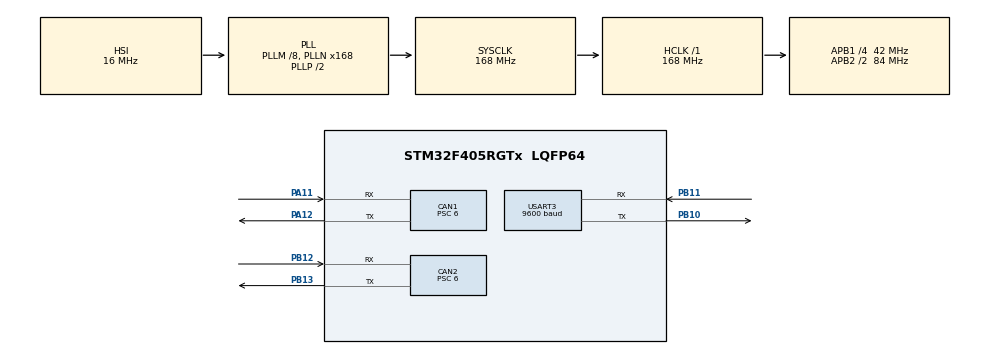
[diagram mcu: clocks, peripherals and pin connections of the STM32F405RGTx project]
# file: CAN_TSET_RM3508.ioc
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CAN1.BS1=CAN_BS1_4TQ
CAN1.BS2=CAN_BS2_2TQ
CAN1.CalculateBaudRate=1000000
CAN1.CalculateTimeBit=1000
CAN1.CalculateTimeQuantum=142.85714285714286
CAN1.Prescaler=6
CAN2.BS1=CAN_BS1_4TQ
CAN2.BS2=CAN_BS2_2TQ
CAN2.CalculateBaudRate=1000000
CAN2.CalculateTimeBit=1000
CAN2.CalculateTimeQuantum=142.85714285714286
CAN2.Prescaler=6
Mcu.Family=STM32F4
Mcu.Name=STM32F405RGTx
Mcu.Package=LQFP64
NVIC.CAN1_RX0_IRQn=true\:0\:0\:false\:false\:true\:true\:true\:true
NVIC.CAN1_SCE_IRQn=true\:0\:0\:false\:false\:true\:true\:true\:true
NVIC.CAN2_RX1_IRQn=true\:0\:0\:false\:false\:true\:true\:true\:true
NVIC.CAN2_SCE_IRQn=true\:0\:0\:false\:false\:true\:true\:true\:true
NVIC.PriorityGroup=NVIC_PRIORITYGROUP_4
NVIC.USART3_IRQn=true\:0\:0\:false\:false\:true\:true\:true\:true
PA11.Mode=CAN_Activate
PA11.Signal=CAN1_RX
PA12.Mode=CAN_Activate
PA12.Signal=CAN1_TX
PA13.Mode=Serial_Wire
PA13.Signal=SYS_JTMS-SWDIO
PA14.Mode=Serial_Wire
PA14.Signal=SYS_JTCK-SWCLK
PB10.Mode=Asynchronous
PB10.Signal=USART3_TX
PB11.Mode=Asynchronous
PB11.Signal=USART3_RX
PB12.Mode=CAN_Activate
PB12.Signal=CAN2_RX
PB13.Mode=CAN_Activate
PB13.Signal=CAN2_TX
PC14-OSC32_IN.Mode=LSE-External-Oscillator
PC14-OSC32_IN.Signal=RCC_OSC32_IN
PC15-OSC32_OUT.Mode=LSE-External-Oscillator
PC15-OSC32_OUT.Signal=RCC_OSC32_OUT
PH0-OSC_IN.Mode=HSE-External-Oscillator
PH0-OSC_IN.Signal=RCC_OSC_IN
PH1-OSC_OUT.Mode=HSE-External-Oscillator
PH1-OSC_OUT.Signal=RCC_OSC_OUT
ProjectManager.HeapSize=0x200
ProjectManager.StackSize=0x400
ProjectManager.TargetToolchain=MDK-ARM V5
RCC.48MHZClocksFreq_Value=84000000
RCC.AHBFreq_Value=168000000
RCC.APB1CLKDivider=RCC_HCLK_DIV4
RCC.APB1Freq_Value=42000000
RCC.APB1TimFreq_Value=84000000
RCC.APB2CLKDivider=RCC_HCLK_DIV2
RCC.APB2Freq_Value=84000000
RCC.APB2TimFreq_Value=168000000
RCC.CortexFreq_Value=168000000
RCC.HCLKFreq_Value=168000000
RCC.HSE_VALUE=25000000
RCC.HSI_VALUE=16000000
RCC.PLLM=8
RCC.PLLN=168
RCC.SYSCLKFreq_VALUE=168000000
RCC.SYSCLKSource=RCC_SYSCLKSOURCE_PLLCLK
RCC.VCOOutputFreq_Value=336000000
USART3.BaudRate=9600
USART3.VirtualMode=VM_ASYNC
board=custom

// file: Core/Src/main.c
/* USER CODE BEGIN Header */
/**
  ******************************************************************************
  * @file           : main.c
  * @brief          : Main program body
  ******************************************************************************
  * @attention
  *
  * Copyright (c) 2023 STMicroelectronics.
  * All rights reserved.
  *
  * This software is licensed under terms that can be found in the LICENSE file
  * in the root directory of this software component.
  * If no LICENSE file comes with this software, it is provided AS-IS.
  *
  ******************************************************************************
  */
/* USER CODE END Header */
#include "main.h"
#include "can.h"
#include "usart.h"
#include "gpio.h"

/* USER CODE BEGIN Includes */
#include "can_bsp.h"
#include "RM3508.h"

/* USER CODE END Includes */

void SystemClock_Config(void);

int main(void)
{

  /* MCU Configuration--------------------------------------------------------*/

  /* Reset of all peripherals, Initializes the Flash interface and the Systick. */
  HAL_Init();

  /* Configure the system clock */
  SystemClock_Config();

  /* Initialize all configured peripherals */
  MX_GPIO_Init();
  MX_CAN1_Init();
  MX_CAN2_Init();
  MX_USART3_UART_Init();
  /* USER CODE BEGIN 2 */
	CAN_Init(&hcan1);
	CAN_Init(&hcan2);

  /* USER CODE END 2 */

  /* Infinite loop */
  while (1)
  {

    /* USER CODE BEGIN 3 */

		RM3508_Set_Speed(1000,0x03);

		HAL_Delay(1);

//		sprintf(txdata, ":%d\n", RM3508_Get_Speed(3));
////		sprintf(target,"%d\n",);
//		HAL_UART_Transmit(&huart3, (uint8_t *)txdata, sizeof(txdata), 10000);
//		HAL_Delay(1);
  }
  /* USER CODE END 3 */
}

void SystemClock_Config(void)
{
  RCC_OscInitTypeDef RCC_OscInitStruct = {0};
  RCC_ClkInitTypeDef RCC_ClkInitStruct = {0};

  /** Configure the main internal regulator output voltage
  */
  __HAL_RCC_PWR_CLK_ENABLE();
  __HAL_PWR_VOLTAGESCALING_CONFIG(PWR_REGULATOR_VOLTAGE_SCALE1);

  /** Initializes the RCC Oscillators according to the specified parameters
  * in the RCC_OscInitTypeDef structure.
  */
  RCC_OscInitStruct.OscillatorType = RCC_OSCILLATORTYPE_HSI;
  RCC_OscInitStruct.HSIState = RCC_HSI_ON;
  RCC_OscInitStruct.HSICalibrationValue = RCC_HSICALIBRATION_DEFAULT;
  RCC_OscInitStruct.PLL.PLLState = RCC_PLL_ON;
  RCC_OscInitStruct.PLL.PLLSource = RCC_PLLSOURCE_HSI;
  RCC_OscInitStruct.PLL.PLLM = 8;
  RCC_OscInitStruct.PLL.PLLN = 168;
  RCC_OscInitStruct.PLL.PLLP = RCC_PLLP_DIV2;
  RCC_OscInitStruct.PLL.PLLQ = 4;
  if (HAL_RCC_OscConfig(&RCC_OscInitStruct) != HAL_OK)
  {
    Error_Handler();
  }

  /** Initializes the CPU, AHB and APB buses clocks
  */
  RCC_ClkInitStruct.ClockType = RCC_CLOCKTYPE_HCLK|RCC_CLOCKTYPE_SYSCLK
                              |RCC_CLOCKTYPE_PCLK1|RCC_CLOCKTYPE_PCLK2;
  RCC_ClkInitStruct.SYSCLKSource = RCC_SYSCLKSOURCE_PLLCLK;
  RCC_ClkInitStruct.AHBCLKDivider = RCC_SYSCLK_DIV1;
  RCC_ClkInitStruct.APB1CLKDivider = RCC_HCLK_DIV4;
  RCC_ClkInitStruct.APB2CLKDivider = RCC_HCLK_DIV2;

  if (HAL_RCC_ClockConfig(&RCC_ClkInitStruct, FLASH_LATENCY_5) != HAL_OK)
  {
    Error_Handler();
  }
}

/* USER CODE BEGIN 4 */

void HAL_CAN_RxFifo0MsgPendingCallback(CAN_HandleTypeDef *hcan)
{
	if(hcan->Instance == hcan1.Instance)
	{
		CAN_RxHeaderTypeDef RxMessage;
		uint8_t RxData[8] = {0};

		HAL_CAN_GetRxMessage(&hcan1, CAN_RX_FIFO0, &RxMessage, RxData);

		if(RxMessage.IDE==CAN_ID_STD)
		{
			if(RxMessage.StdId>=0x201&&RxMessage.StdId<=0x208)
			{
				RM3508_Get_Feedback(RxMessage.StdId, RxData);
			}
		}
		/*�Լ�д��������*/

	}
}
/* USER CODE END 4 */

void Error_Handler(void)
{
  /* USER CODE BEGIN Error_Handler_Debug */
  /* User can add his own implementation to report the HAL error return state */
  __disable_irq();
//  while (1)
//  {
//  }
  /* USER CODE END Error_Handler_Debug */
}
